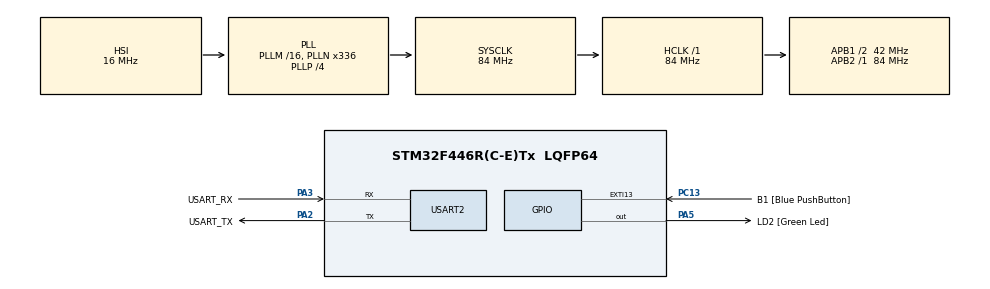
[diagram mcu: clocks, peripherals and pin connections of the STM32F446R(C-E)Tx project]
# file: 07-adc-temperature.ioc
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ADC1.Channel-3\#ChannelRegularConversion=ADC_CHANNEL_TEMPSENSOR
ADC1.Channel-4\#ChannelInjectedConversion=ADC_CHANNEL_TEMPSENSOR
ADC1.InjNumberOfConversion=1
ADC1.InjectedOffset-4\#ChannelInjectedConversion=0
ADC1.InjectedRank-4\#ChannelInjectedConversion=1
ADC1.NbrOfConversion=1
ADC1.NbrOfConversionFlag=1
ADC1.Rank-3\#ChannelRegularConversion=1
ADC1.SamplingTime-3\#ChannelRegularConversion=ADC_SAMPLETIME_480CYCLES
ADC1.SamplingTime-4\#ChannelInjectedConversion=ADC_SAMPLETIME_3CYCLES
ADC1.master=1
Mcu.Family=STM32F4
Mcu.Name=STM32F446R(C-E)Tx
Mcu.Package=LQFP64
NVIC.PriorityGroup=NVIC_PRIORITYGROUP_0
PA13.GPIO_Label=TMS
PA13.Mode=Serial_Wire
PA13.Signal=SYS_JTMS-SWDIO
PA14.GPIO_Label=TCK
PA14.Mode=Serial_Wire
PA14.Signal=SYS_JTCK-SWCLK
PA2.GPIO_Label=USART_TX
PA2.Mode=Asynchronous
PA2.Signal=USART2_TX
PA3.GPIO_Label=USART_RX
PA3.Mode=Asynchronous
PA3.Signal=USART2_RX
PA5.GPIO_Label=LD2 [Green Led]
PA5.Signal=GPIO_Output
PB3.GPIO_Label=SWO
PB3.Signal=SYS_JTDO-SWO
PC13.GPIO_Label=B1 [Blue PushButton]
PC13.GPIO_ModeDefaultEXTI=GPIO_MODE_IT_FALLING
PC13.Signal=GPXTI13
PC14-OSC32_IN.Mode=LSE-External-Oscillator
PC14-OSC32_IN.Signal=RCC_OSC32_IN
PC15-OSC32_OUT.Mode=LSE-External-Oscillator
PC15-OSC32_OUT.Signal=RCC_OSC32_OUT
PH0-OSC_IN.Mode=HSE-External-Oscillator
PH0-OSC_IN.Signal=RCC_OSC_IN
PH1-OSC_OUT.Mode=HSE-External-Oscillator
PH1-OSC_OUT.Signal=RCC_OSC_OUT
ProjectManager.HeapSize=0x200
ProjectManager.StackSize=0x400
ProjectManager.TargetToolchain=STM32CubeIDE
RCC.48MHZClocksFreq_Value=84000000
RCC.AHBFreq_Value=84000000
RCC.APB1CLKDivider=RCC_HCLK_DIV2
RCC.APB1Freq_Value=42000000
RCC.APB1TimFreq_Value=84000000
RCC.APB2Freq_Value=84000000
RCC.APB2TimFreq_Value=84000000
RCC.CortexFreq_Value=84000000
RCC.FLatency-AdvancedSettings=FLASH_LATENCY_2
RCC.HCLKFreq_Value=84000000
RCC.HSE_VALUE=8000000
RCC.HSI_VALUE=16000000
RCC.PLLN=336
RCC.PLLP=RCC_PLLP_DIV4
RCC.SYSCLKFreq_VALUE=84000000
RCC.SYSCLKSource=RCC_SYSCLKSOURCE_PLLCLK
RCC.USBFreq_Value=168000000
RCC.VCOOutputFreq_Value=336000000
USART2.VirtualMode=VM_ASYNC
VP_ADC1_TempSens_Input.Mode=IN-TempSens
board=NUCLEO-F446RE

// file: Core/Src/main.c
/* USER CODE BEGIN Header */
/**
  ******************************************************************************
  * @file           : main.c
  * @brief          : Main program body
  ******************************************************************************
  * @attention
  *
  * Copyright (c) 2026 STMicroelectronics.
  * All rights reserved.
  *
  * This software is licensed under terms that can be found in the LICENSE file
  * in the root directory of this software component.
  * If no LICENSE file comes with this software, it is provided AS-IS.
  *
  ******************************************************************************
  */
/* USER CODE END Header */
#include "main.h"

/* USER CODE BEGIN Includes */
#include <stdio.h>
/* USER CODE END Includes */

ADC_HandleTypeDef hadc1;

UART_HandleTypeDef huart2;

void SystemClock_Config(void);
static void MX_GPIO_Init(void);
static void MX_USART2_UART_Init(void);
static void MX_ADC1_Init(void);

int main(void)
{

  /* MCU Configuration--------------------------------------------------------*/

  /* Reset of all peripherals, Initializes the Flash interface and the Systick. */
  HAL_Init();

  /* Configure the system clock */
  SystemClock_Config();

  /* Initialize all configured peripherals */
  MX_GPIO_Init();
  MX_USART2_UART_Init();
  MX_ADC1_Init();
  /* USER CODE BEGIN 2 */
  printf("\r\nBoard started\r\n");
//  HAL_ADC_Start(&hadc1);  // 1. Start the ADC
  /* USER CODE END 2 */

  /* Infinite loop */
  while (1)
  {

    /* USER CODE BEGIN 3 */

	// Refer to page 376 in the Reference Manual and
	// page 145 in the Datasheet
	HAL_ADC_Start(&hadc1);  // 1. Start the ADC
	if (HAL_ADC_PollForConversion(&hadc1, 100) == HAL_OK)  // 2. Wait up to 100 ms for completion
	{
		uint32_t adc_value = HAL_ADC_GetValue(&hadc1);  // 3. Read the raw converted value
		float v_sense = (adc_value * 3.3) / 4096;  // 4. Converted to Voltage V_SENSE
		float temp = (v_sense - 0.76) / (2.5 / 1000) + 25;  // 5. Temperature reading
		printf("raw=%4d  v=%.3f  T=%.1f C\r\n", (int)adc_value, v_sense, temp);
	}
	HAL_ADC_Stop(&hadc1);
	HAL_Delay(1000);
  }
  /* USER CODE END 3 */
}

void SystemClock_Config(void)
{
  RCC_OscInitTypeDef RCC_OscInitStruct = {0};
  RCC_ClkInitTypeDef RCC_ClkInitStruct = {0};

  /** Configure the main internal regulator output voltage
  */
  __HAL_RCC_PWR_CLK_ENABLE();
  __HAL_PWR_VOLTAGESCALING_CONFIG(PWR_REGULATOR_VOLTAGE_SCALE3);

  /** Initializes the RCC Oscillators according to the specified parameters
  * in the RCC_OscInitTypeDef structure.
  */
  RCC_OscInitStruct.OscillatorType = RCC_OSCILLATORTYPE_HSI;
  RCC_OscInitStruct.HSIState = RCC_HSI_ON;
  RCC_OscInitStruct.HSICalibrationValue = RCC_HSICALIBRATION_DEFAULT;
  RCC_OscInitStruct.PLL.PLLState = RCC_PLL_ON;
  RCC_OscInitStruct.PLL.PLLSource = RCC_PLLSOURCE_HSI;
  RCC_OscInitStruct.PLL.PLLM = 16;
  RCC_OscInitStruct.PLL.PLLN = 336;
  RCC_OscInitStruct.PLL.PLLP = RCC_PLLP_DIV4;
  RCC_OscInitStruct.PLL.PLLQ = 2;
  RCC_OscInitStruct.PLL.PLLR = 2;
  if (HAL_RCC_OscConfig(&RCC_OscInitStruct) != HAL_OK)
  {
    Error_Handler();
  }

  /** Initializes the CPU, AHB and APB buses clocks
  */
  RCC_ClkInitStruct.ClockType = RCC_CLOCKTYPE_HCLK|RCC_CLOCKTYPE_SYSCLK
                              |RCC_CLOCKTYPE_PCLK1|RCC_CLOCKTYPE_PCLK2;
  RCC_ClkInitStruct.SYSCLKSource = RCC_SYSCLKSOURCE_PLLCLK;
  RCC_ClkInitStruct.AHBCLKDivider = RCC_SYSCLK_DIV1;
  RCC_ClkInitStruct.APB1CLKDivider = RCC_HCLK_DIV2;
  RCC_ClkInitStruct.APB2CLKDivider = RCC_HCLK_DIV1;

  if (HAL_RCC_ClockConfig(&RCC_ClkInitStruct, FLASH_LATENCY_2) != HAL_OK)
  {
    Error_Handler();
  }
}

static void MX_ADC1_Init(void)
{

  ADC_ChannelConfTypeDef sConfig = {0};
  ADC_InjectionConfTypeDef sConfigInjected = {0};

  /** Configure the global features of the ADC (Clock, Resolution, Data Alignment and number of conversion)
  */
  hadc1.Instance = ADC1;
  hadc1.Init.ClockPrescaler = ADC_CLOCK_SYNC_PCLK_DIV4;
  hadc1.Init.Resolution = ADC_RESOLUTION_12B;
  hadc1.Init.ScanConvMode = DISABLE;
  hadc1.Init.ContinuousConvMode = DISABLE;
  hadc1.Init.DiscontinuousConvMode = DISABLE;
  hadc1.Init.ExternalTrigConvEdge = ADC_EXTERNALTRIGCONVEDGE_NONE;
  hadc1.Init.ExternalTrigConv = ADC_SOFTWARE_START;
  hadc1.Init.DataAlign = ADC_DATAALIGN_RIGHT;
  hadc1.Init.NbrOfConversion = 1;
  hadc1.Init.DMAContinuousRequests = DISABLE;
  hadc1.Init.EOCSelection = ADC_EOC_SINGLE_CONV;
  if (HAL_ADC_Init(&hadc1) != HAL_OK)
  {
    Error_Handler();
  }

  /** Configure for the selected ADC regular channel its corresponding rank in the sequencer and its sample time.
  */
  sConfig.Channel = ADC_CHANNEL_TEMPSENSOR;
  sConfig.Rank = 1;
  sConfig.SamplingTime = ADC_SAMPLETIME_480CYCLES;
  if (HAL_ADC_ConfigChannel(&hadc1, &sConfig) != HAL_OK)
  {
    Error_Handler();
  }

  /** Configures for the selected ADC injected channel its corresponding rank in the sequencer and its sample time
  */
  sConfigInjected.InjectedChannel = ADC_CHANNEL_TEMPSENSOR;
  sConfigInjected.InjectedRank = 1;
  sConfigInjected.InjectedNbrOfConversion = 1;
  sConfigInjected.InjectedSamplingTime = ADC_SAMPLETIME_3CYCLES;
  sConfigInjected.ExternalTrigInjecConvEdge = ADC_EXTERNALTRIGINJECCONVEDGE_NONE;
  sConfigInjected.ExternalTrigInjecConv = ADC_INJECTED_SOFTWARE_START;
  sConfigInjected.AutoInjectedConv = DISABLE;
  sConfigInjected.InjectedDiscontinuousConvMode = DISABLE;
  sConfigInjected.InjectedOffset = 0;
  if (HAL_ADCEx_InjectedConfigChannel(&hadc1, &sConfigInjected) != HAL_OK)
  {
    Error_Handler();
  }

}

static void MX_USART2_UART_Init(void)
{

  huart2.Instance = USART2;
  huart2.Init.BaudRate = 115200;
  huart2.Init.WordLength = UART_WORDLENGTH_8B;
  huart2.Init.StopBits = UART_STOPBITS_1;
  huart2.Init.Parity = UART_PARITY_NONE;
  huart2.Init.Mode = UART_MODE_TX_RX;
  huart2.Init.HwFlowCtl = UART_HWCONTROL_NONE;
  huart2.Init.OverSampling = UART_OVERSAMPLING_16;
  if (HAL_UART_Init(&huart2) != HAL_OK)
  {
    Error_Handler();
  }

}

static void MX_GPIO_Init(void)
{
  GPIO_InitTypeDef GPIO_InitStruct = {0};

  /* GPIO Ports Clock Enable */
  __HAL_RCC_GPIOC_CLK_ENABLE();
  __HAL_RCC_GPIOH_CLK_ENABLE();
  __HAL_RCC_GPIOA_CLK_ENABLE();
  __HAL_RCC_GPIOB_CLK_ENABLE();

  /*Configure GPIO pin Output Level */
  HAL_GPIO_WritePin(LD2_GPIO_Port, LD2_Pin, GPIO_PIN_RESET);

  /*Configure GPIO pin : B1_Pin */
  GPIO_InitStruct.Pin = B1_Pin;
  GPIO_InitStruct.Mode = GPIO_MODE_IT_FALLING;
  GPIO_InitStruct.Pull = GPIO_NOPULL;
  HAL_GPIO_Init(B1_GPIO_Port, &GPIO_InitStruct);

  /*Configure GPIO pin : LD2_Pin */
  GPIO_InitStruct.Pin = LD2_Pin;
  GPIO_InitStruct.Mode = GPIO_MODE_OUTPUT_PP;
  GPIO_InitStruct.Pull = GPIO_NOPULL;
  GPIO_InitStruct.Speed = GPIO_SPEED_FREQ_LOW;
  HAL_GPIO_Init(LD2_GPIO_Port, &GPIO_InitStruct);

}

/* USER CODE BEGIN 4 */
int _write(int file, char *ptr, int len)
{
	HAL_UART_Transmit(&huart2, (uint8_t *)ptr, len, HAL_MAX_DELAY);
	return len;
}
/* USER CODE END 4 */

void Error_Handler(void)
{
  __disable_irq();
  while (1)
  {
  }
}
